# WKUPAON_CM register map
Vendor: Texas Instruments
Peripheral module from a debugger description file (folder am571x).
Registers are 32-bit, read-only, reset 0x30001 unless marked. A register's access mark holds for its fields unless they carry their own. Offsets are as the file gives them; lines under a group give offsets from that group; [hi:lo] are bit positions; {n}, {i} and the like mark numbered series; 'fields as' and 'values as' point back to an identical list; <NAME> marks a mode.

## WKUPAON_CM
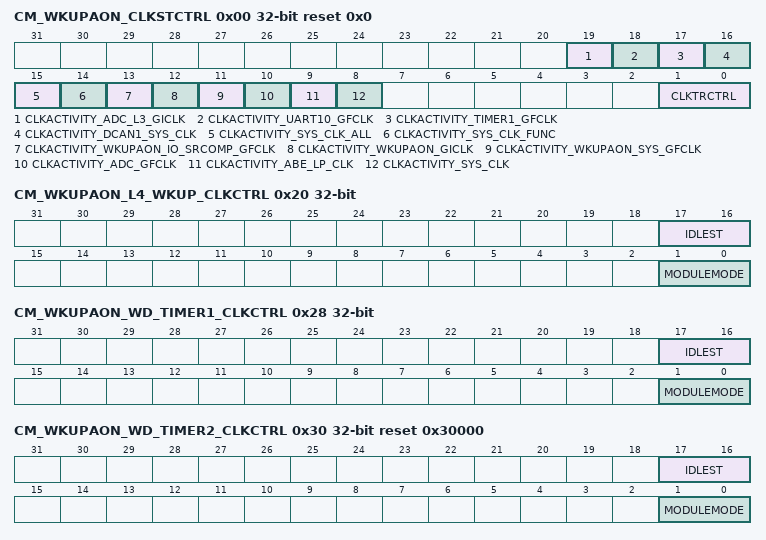
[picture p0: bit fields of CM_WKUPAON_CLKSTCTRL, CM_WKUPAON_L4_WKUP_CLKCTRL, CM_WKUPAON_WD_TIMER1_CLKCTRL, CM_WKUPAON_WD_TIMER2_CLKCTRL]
0x00 CM_WKUPAON_CLKSTCTRL access per field reset 0x0 — This register enables the domain power state transition. It controls the HW supervised domain power state transition between ON-ACTIVE and ON-INACTIVE states. It also hold one status bit per clock input of the domain.
  [19] CLKACTIVITY_ADC_L3_GICLK ro — This field indicates the state of the ADC_L3_GICLK clock in the domain(it includes profiling, EMU_SYS_GCLK and all functional SYS_CLK. [warm reset insensitive]
    0=INACT (Corresponding clock is definitely gated); 1=ACT (Corresponding clock is running or gating/ungating transition is on-going)
  [18] CLKACTIVITY_UART10_GFCLK ro — This field indicates the state of the UART10_GFCLK clock in the domain. [warm reset insensitive]
    values as CLKACTIVITY_ADC_L3_GICLK
  [17] CLKACTIVITY_TIMER1_GFCLK ro — This field indicates the state of the TIMER1_GFCLK clock in the domain. [warm reset insensitive]
    values as CLKACTIVITY_ADC_L3_GICLK
  [16] CLKACTIVITY_DCAN1_SYS_CLK ro — This field indicates the state of the DCAN1_SYS_CLK clock in the domain. [warm reset insensitive]
    values as CLKACTIVITY_ADC_L3_GICLK
  [15] CLKACTIVITY_SYS_CLK_ALL ro — This field indicates the state of the SYS_CLK runing at SCRM level because of any SCRM clock request. [warm reset insensitive]
    values as CLKACTIVITY_ADC_L3_GICLK
  [14] CLKACTIVITY_SYS_CLK_FUNC ro — This field indicates the state of the functional SYS_CLK clocks in the domain (this exclude activity of EMU_GCLK clock). [warm reset insensitive]
    values as CLKACTIVITY_ADC_L3_GICLK
  [13] CLKACTIVITY_WKUPAON_IO_SRCOMP_GFCLK ro — This field indicates the state of the WKUPAON_IO_SRCOMP_GFCLK clock in the domain. [warm reset insensitive]
    values as CLKACTIVITY_ADC_L3_GICLK
  [12] CLKACTIVITY_WKUPAON_GICLK ro — This field indicates the state of the WKUPAON_GICLK clock in the domain. [warm reset insensitive]
    values as CLKACTIVITY_ADC_L3_GICLK
  [11] CLKACTIVITY_WKUPAON_SYS_GFCLK ro — This field indicates the state of the WKUPAON_SYS_GFCLK clock in the domain. [warm reset insensitive]
    values as CLKACTIVITY_ADC_L3_GICLK
  [10] CLKACTIVITY_ADC_GFCLK ro — This field indicates the state of the ADC_GFCLK clock in the domain. [warm reset insensitive]
    values as CLKACTIVITY_ADC_L3_GICLK
  [9] CLKACTIVITY_ABE_LP_CLK ro — This field indicates the state of the ABE_LP_CLK clock in the domain. [warm reset insensitive]
    values as CLKACTIVITY_ADC_L3_GICLK
  [8] CLKACTIVITY_SYS_CLK ro — This field indicates the state of the SYS_CLK clock in the domain(it includes profiling, EMU_SYS_GCLK and all functional SYS_CLK. [warm reset insensitive]
    values as CLKACTIVITY_ADC_L3_GICLK
  [1:0] CLKTRCTRL rw — Controls the clock state transition of the WKUPAON clock domain.
    0=NO_SLEEP (NO_SLEEP: Sleep transition cannot be initiated. Wakeup transition may however occur.); 2=SW_WKUP (SW_WKUP: Start a software forced wake-up transition on the domain.); 3=HW_AUTO (HW_AUTO: Automatic transition is enabled. Sleep and wakeup transition are based upon hardware conditions.)
0x20 CM_WKUPAON_L4_WKUP_CLKCTRL — This register manages the WKUPAON clocks.
  [17:16] IDLEST — Module idle status. [warm reset insensitive]
    0=FUNC (Module is fully functional, including OCP); 1=TRANS (Module is performing transition: wakeup, or sleep, or sleep abortion); 2=IDLE (Module is in Idle mode (only OCP part). It is functional if using separate functional clock); 3=DISABLE (Module is disabled and cannot be accessed)
  [1:0] MODULEMODE — Control the way mandatory clocks are managed.
    1=AUTO (Module is managed automatically by HW according to clock domain transition. A clock domain sleep transition put module into idle. A wakeup domain transition put it back into function. If CLKTRCTRL=3, any OCP access to module is always granted. Module clocks may be gated according to the clock domain state.)
0x28 CM_WKUPAON_WD_TIMER1_CLKCTRL — This register manages the WD_TIMER1 clocks.
  fields as CM_WKUPAON_L4_WKUP_CLKCTRL
0x30 CM_WKUPAON_WD_TIMER2_CLKCTRL access per field reset 0x30000 — This register manages the WD_TIMER2 clocks.
  [17:16] IDLEST ro — Module idle status. [warm reset insensitive]
    values as CM_WKUPAON_L4_WKUP_CLKCTRL.IDLEST
  [1:0] MODULEMODE rw — Control the way mandatory clocks are managed.
    0=DISABLED (Module is disabled by SW. Any OCP access to module results in an error, except if resulting from a module wakeup (asynchronous wakeup).); 2=ENABLE (Module is explicitly enabled. Interface clock (if not used for functions) may be gated according to the clock domain state. Functional clocks are guaranteed to stay present. As long as in this configuration, power domain sleep transition cannot happen.)
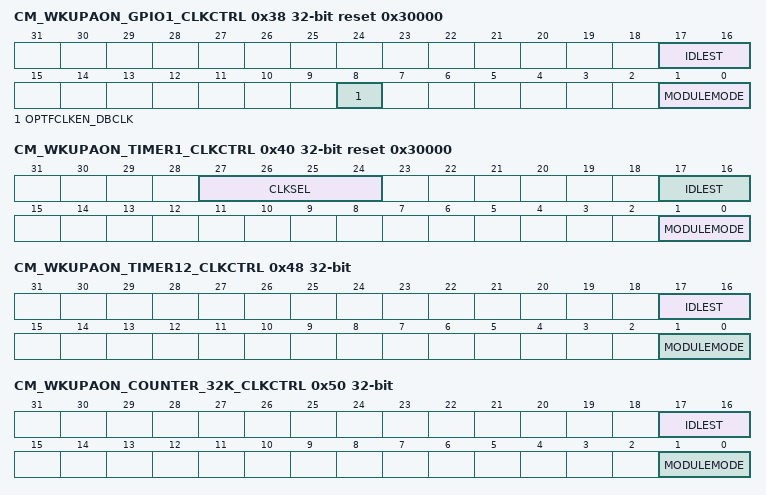
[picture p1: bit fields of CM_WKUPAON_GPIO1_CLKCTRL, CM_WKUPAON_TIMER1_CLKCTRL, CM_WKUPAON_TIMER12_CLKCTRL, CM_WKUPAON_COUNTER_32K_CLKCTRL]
0x38 CM_WKUPAON_GPIO1_CLKCTRL access per field reset 0x30000 — This register manages the GPIO1 clocks.
  [17:16] IDLEST ro — Module idle status. [warm reset insensitive]
    values as CM_WKUPAON_L4_WKUP_CLKCTRL.IDLEST
  [8] OPTFCLKEN_DBCLK rw — Optional functional clock control.
    0=FCLK_DIS (Optional functional clock is disabled); 1=FCLK_EN (Optional functional clock is enabled)
  [1:0] MODULEMODE rw — Control the way mandatory clocks are managed.
    0=DISABLED (Module is disabled by SW. Any OCP access to module results in an error, except if resulting from a module wakeup (asynchronous wakeup).); 1=AUTO (Module is managed automatically by HW according to clock domain transition. A clock domain sleep transition put module into idle. A wakeup domain transition put it back into function. If CLKTRCTRL=3, any OCP access to module is always granted. Module clocks may be gated according to the clock domain state.)
0x40 CM_WKUPAON_TIMER1_CLKCTRL access per field reset 0x30000 — This register manages the TIMER1 clocks.
  [27:24] CLKSEL rw — Select the source of the functional clock0xB-0xF: RESERVED enum=RESERVED4 .
    0=SEL_TIMER_SYS_CLK (Selects the TIMER_SYS_CLK); 1=SEL_SYS_CLK1_32K_CLK (Selects the FUNC_32K_CLK); 2=SEL_SYS_CLK2 (Selects SYS_CLK2); {v}=SEL_XREF_CLK{v-3} (Selects XREF_CLK{v-3}) (v=3..6); 7=SEL_PER_ABE_X1_GFCLK (Selects ABE_GICLK); 8=SEL_VIDEO1_CLK (Selects VIDEO1_DIV_CLK); 9=SEL_VIDEO2_CLK (Selects VIDEO2_DIV_CLK); 10=SEL_HDMI_CLK (Selects HDMI_DIV_CLK)
  [17:16] IDLEST ro — Module idle status. [warm reset insensitive]
    values as CM_WKUPAON_L4_WKUP_CLKCTRL.IDLEST
  [1:0] MODULEMODE rw — Control the way mandatory clocks are managed.
    values as CM_WKUPAON_WD_TIMER2_CLKCTRL.MODULEMODE
0x48 CM_WKUPAON_TIMER12_CLKCTRL — This register manages the TIMER12 clocks.
  fields as CM_WKUPAON_L4_WKUP_CLKCTRL
0x50 CM_WKUPAON_COUNTER_32K_CLKCTRL — This register manages the COUNTER_32K clocks.
  fields as CM_WKUPAON_L4_WKUP_CLKCTRL
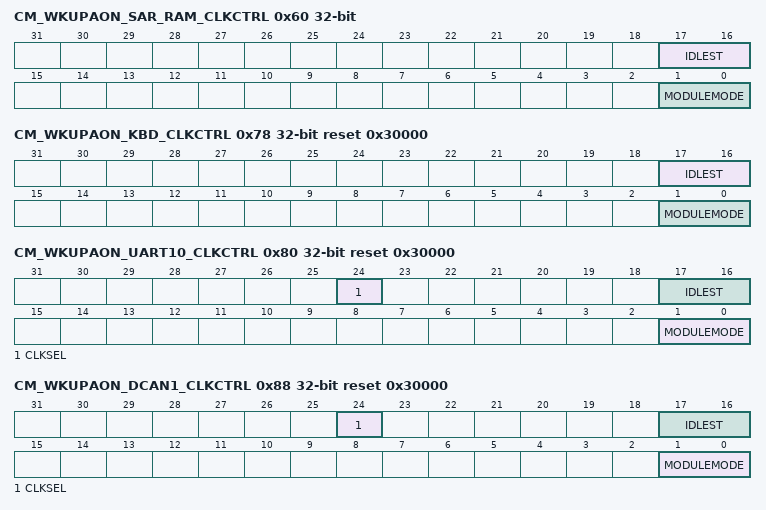
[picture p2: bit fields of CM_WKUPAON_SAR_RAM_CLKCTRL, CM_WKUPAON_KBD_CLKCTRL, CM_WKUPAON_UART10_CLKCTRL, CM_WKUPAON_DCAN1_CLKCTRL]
0x60 CM_WKUPAON_SAR_RAM_CLKCTRL — This register manages the SAR_RAM clocks.
  fields as CM_WKUPAON_L4_WKUP_CLKCTRL
0x78 CM_WKUPAON_KBD_CLKCTRL access per field reset 0x30000 — This register manages the KBD clocks.
  fields as CM_WKUPAON_WD_TIMER2_CLKCTRL
0x80 CM_WKUPAON_UART10_CLKCTRL access per field reset 0x30000 — This register manages the UART10 clocks.
  [24] CLKSEL rw — Selects functional clock for UART10 between FUNC_48M_FCLK and FUNC_192M_CLK
    0=SEL_FUNC_48M_CLK (Selects FUNC_48M_FCLK); 1=SEL_FUNC_192M_CLK (Selects FUNC_192M_CLK)
  [17:16] IDLEST ro — Module idle status. [warm reset insensitive]
    values as CM_WKUPAON_L4_WKUP_CLKCTRL.IDLEST
  [1:0] MODULEMODE rw — Control the way mandatory clocks are managed.
    values as CM_WKUPAON_WD_TIMER2_CLKCTRL.MODULEMODE
0x88 CM_WKUPAON_DCAN1_CLKCTRL access per field reset 0x30000 — This register manages the DCAN1 clocks.
  [24] CLKSEL rw — Selects SYS clock for DCAN1 between SYS_CLK1 and SYS_CLK2
    0=SEL_SYS_CLK1 (Selects SYS_CLK1); 1=SEL_SYS_CLK2 (Selects SYS_CLK2)
  [17:16] IDLEST ro — Module idle status. [warm reset insensitive]
    values as CM_WKUPAON_L4_WKUP_CLKCTRL.IDLEST
  [1:0] MODULEMODE rw — Control the way mandatory clocks are managed.
    values as CM_WKUPAON_WD_TIMER2_CLKCTRL.MODULEMODE
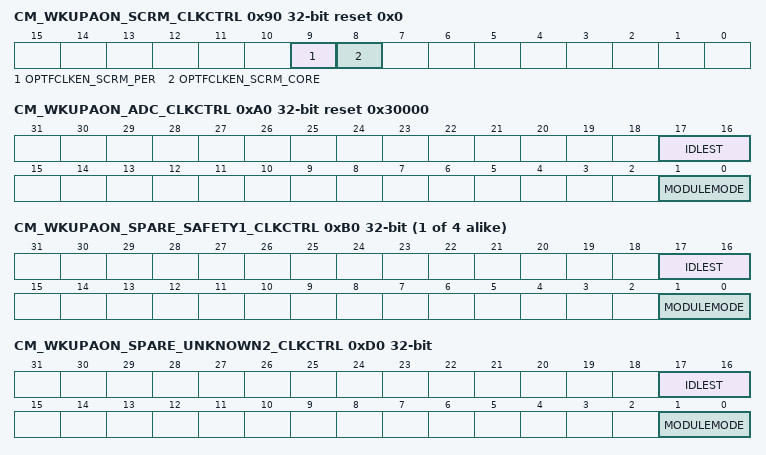
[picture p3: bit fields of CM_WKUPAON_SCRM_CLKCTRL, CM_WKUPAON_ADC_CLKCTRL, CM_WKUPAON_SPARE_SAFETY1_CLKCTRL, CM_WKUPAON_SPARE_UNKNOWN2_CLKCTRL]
0x90 CM_WKUPAON_SCRM_CLKCTRL access per field reset 0x0 — This register manages the SCRM clocks.
  [9] OPTFCLKEN_SCRM_PER rw — Optional functional clock control.
    values as CM_WKUPAON_GPIO1_CLKCTRL.OPTFCLKEN_DBCLK
  [8] OPTFCLKEN_SCRM_CORE rw — Optional functional clock control.
    values as CM_WKUPAON_GPIO1_CLKCTRL.OPTFCLKEN_DBCLK
0x98 CM_WKUPAON_IO_SRCOMP_CLKCTRL access per field reset 0x0 — This register manages the clock delivered to the IO Slew rate compensation cells. [warm reset insensitive]
  [8] CLKEN_SRCOMP_FCLK rw — Functional clock control.
    0=FCLK_DIS (Functional clock is disabled); 1=FCLK_EN (Functional clock is enabled.)
0xA0 CM_WKUPAON_ADC_CLKCTRL access per field reset 0x30000 — This register manages the ADC clocks.
  fields as CM_WKUPAON_WD_TIMER2_CLKCTRL
{0xA8+8i} CM_WKUPAON_SPARE_SAFETY{i}_CLKCTRL (i=1..4) — This register manages the SPARE_SAFETY{i} clocks.
  fields as CM_WKUPAON_L4_WKUP_CLKCTRL
0xD0 CM_WKUPAON_SPARE_UNKNOWN2_CLKCTRL — This register manages the SPARE_UNKNOWN2 clocks.
  fields as CM_WKUPAON_L4_WKUP_CLKCTRL
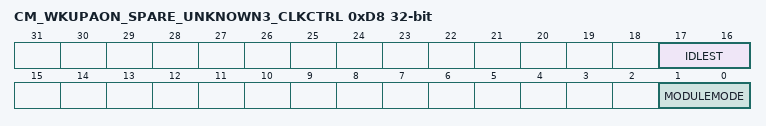
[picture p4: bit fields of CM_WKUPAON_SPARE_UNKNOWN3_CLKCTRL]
0xD8 CM_WKUPAON_SPARE_UNKNOWN3_CLKCTRL — This register manages the SPARE_UNKNOWN3 clocks.
  fields as CM_WKUPAON_L4_WKUP_CLKCTRL
